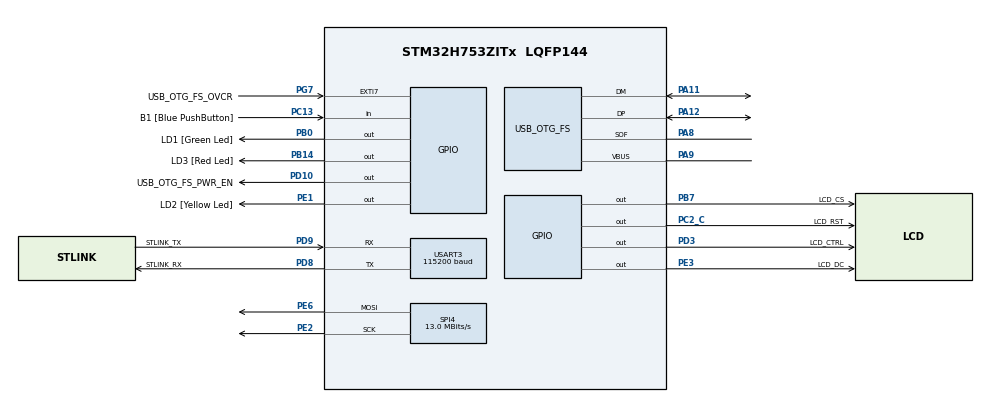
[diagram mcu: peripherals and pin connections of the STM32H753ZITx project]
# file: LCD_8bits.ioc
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CORTEX_M7.CPU_DCache=Disabled
CORTEX_M7.CPU_ICache=Disabled
CORTEX_M7.MPU_Control=__NULL
Mcu.Family=STM32H7
Mcu.Name=STM32H753ZITx
Mcu.Package=LQFP144
NVIC.PriorityGroup=NVIC_PRIORITYGROUP_4
PA1.Signal=ETH_REF_CLK
PA11.Mode=Device_Only
PA11.Signal=USB_OTG_FS_DM
PA12.Mode=Device_Only
PA12.Signal=USB_OTG_FS_DP
PA2.Signal=ETH_MDIO
PA7.Signal=ETH_CRS_DV
PA8.Mode=Activate_SOF_FS
PA8.Signal=USB_OTG_FS_SOF
PA9.Mode=Activate_VBUS
PA9.Signal=USB_OTG_FS_VBUS
PB0.GPIO_Label=LD1 [Green Led]
PB0.Signal=GPIO_Output
PB13.Signal=ETH_TXD1
PB14.GPIO_Label=LD3 [Red Led]
PB14.Signal=GPIO_Output
PB7.GPIO_FM7=__NULL
PB7.GPIO_Label=LCD_CS
PB7.GPIO_Speed=GPIO_SPEED_FREQ_HIGH
PB7.Signal=GPIO_Output
PC1.Signal=ETH_MDC
PC13.GPIO_Label=B1 [Blue PushButton]
PC13.Signal=GPIO_Input
PC14-OSC32_IN\ (OSC32_IN).Mode=LSE-External-Oscillator
PC14-OSC32_IN\ (OSC32_IN).Signal=RCC_OSC32_IN
PC15-OSC32_OUT\ (OSC32_OUT).Mode=LSE-External-Oscillator
PC15-OSC32_OUT\ (OSC32_OUT).Signal=RCC_OSC32_OUT
PC2_C.GPIO_Label=LCD_RST
PC2_C.GPIO_Speed=GPIO_SPEED_FREQ_HIGH
PC2_C.PinState=GPIO_PIN_SET
PC2_C.Signal=GPIO_Output
PC4.Signal=ETH_RXD0
PC5.Signal=ETH_RXD1
PD10.GPIO_Label=USB_OTG_FS_PWR_EN
PD10.Signal=GPIO_Output
PD3.GPIO_Label=LCD_CTRL
PD3.Signal=GPIO_Output
PD8.GPIO_Label=STLINK_RX
PD8.Mode=Asynchronous
PD8.Signal=USART3_TX
PD9.GPIO_Label=STLINK_TX
PD9.Mode=Asynchronous
PD9.Signal=USART3_RX
PE1.GPIO_Label=LD2 [Yellow Led]
PE1.Signal=GPIO_Output
PE2.Mode=TX_Only_Simplex_Unidirect_Master
PE2.Signal=SPI4_SCK
PE3.GPIO_Label=LCD_DC
PE3.Signal=GPIO_Output
PE6.Mode=TX_Only_Simplex_Unidirect_Master
PE6.Signal=SPI4_MOSI
PG11.Signal=ETH_TX_EN
PG13.Signal=ETH_TXD0
PG7.GPIO_Label=USB_OTG_FS_OVCR
PG7.Signal=GPXTI7
PH0-OSC_IN\ (PH0).Mode=HSE-External-Clock-Source
PH0-OSC_IN\ (PH0).Signal=RCC_OSC_IN
PH1-OSC_OUT\ (PH1).Signal=RCC_OSC_OUT
ProjectManager.HeapSize=0x2000
ProjectManager.StackSize=0x4000
ProjectManager.TargetToolchain=MDK-ARM V5.32
RCC.ADCFreq_Value=16375000
RCC.APB1Freq_Value=52000000
RCC.APB2Freq_Value=52000000
RCC.APB3Freq_Value=104000000
RCC.APB4Freq_Value=104000000
RCC.CortexFreq_Value=26000000
RCC.Cortex_Div=SYSTICK_CLKSOURCE_HCLK_DIV8
RCC.D2PPRE1=RCC_APB1_DIV2
RCC.D2PPRE2=RCC_APB2_DIV2
RCC.DIVM1=1
RCC.DIVN1=52
RCC.DIVN2=131
RCC.DIVQ1=7
RCC.HCLKFreq_Value=104000000
RCC.HPRE=RCC_HCLK_DIV2
RCC.HSE_VALUE=8000000
RCC.PLLFRACN=0
RCC.PWR_Regulator_Voltage_Scale=PWR_REGULATOR_VOLTAGE_SCALE2
RCC.SYSCLKFreq_VALUE=208000000
RCC.SYSCLKSource=RCC_SYSCLKSOURCE_PLLCLK
RCC.USBFreq_Value=59428571.428571425
SPI4.BaudRatePrescaler=SPI_BAUDRATEPRESCALER_4
SPI4.CalculateBaudRate=13.0 MBits/s
SPI4.DataSize=SPI_DATASIZE_16BIT
SPI4.Direction=SPI_DIRECTION_2LINES_TXONLY
SPI4.Mode=SPI_MODE_MASTER
SPI4.VirtualType=VM_MASTER
USART3.AutoBaudRateEnableParam=UART_ADVFEATURE_AUTOBAUDRATE_DISABLE
USART3.BaudRate=115200
USART3.ClockPrescaler=PRESCALER_DIV1
USART3.DMADisableonRxErrorParam=ADVFEATURE_DMA_ENABLEONRXERROR
USART3.DataInvertParam=ADVFEATURE_DATAINV_DISABLE
USART3.FIFOMode=FIFOMODE_DISABLE
USART3.MSBFirstParam=ADVFEATURE_MSBFIRST_DISABLE
USART3.Mode=MODE_TX_RX
USART3.OneBitSampling=UART_ONE_BIT_SAMPLE_DISABLE
USART3.OverSampling=UART_OVERSAMPLING_16
USART3.OverrunDisableParam=ADVFEATURE_OVERRUN_ENABLE
USART3.Parity=PARITY_NONE
USART3.RXFIFOThreshold=RXFIFO_THRESHOLD_1EIGHTHFULL
USART3.RxPinLevelInvertParam=ADVFEATURE_RXINV_DISABLE
USART3.StopBits=STOPBITS_1
USART3.SwapParam=ADVFEATURE_SWAP_DISABLE
USART3.TXFIFOThreshold=TXFIFO_THRESHOLD_1EIGHTHFULL
USART3.TxPinLevelInvertParam=ADVFEATURE_TXINV_DISABLE
USART3.VirtualMode-Asynchronous=VM_ASYNC
USART3.WordLength=WORDLENGTH_8B
USB_OTG_FS.Sof_enable=ENABLE
USB_OTG_FS.VirtualMode=Device_Only
USB_OTG_FS.battery_charging_enable=ENABLE
USB_OTG_FS.low_power_enable=DISABLE
USB_OTG_FS.lpm_enable=DISABLE
USB_OTG_FS.use_dedicated_ep1=DISABLE
USB_OTG_FS.vbus_sensing_enable=ENABLE
VP_CRC_VS_CRC.Mode=CRC_Activate
board=NUCLEO-H753ZI

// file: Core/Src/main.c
/* USER CODE BEGIN Header */
/**
  ******************************************************************************
  * @file           : main.c
  * @brief          : Main program body
  ******************************************************************************
  * @attention
  *
  * Copyright (c) 2024 STMicroelectronics.
  * All rights reserved.
  *
  * This software is licensed under terms that can be found in the LICENSE file
  * in the root directory of this software component.
  * If no LICENSE file comes with this software, it is provided AS-IS.
  *
  ******************************************************************************
  */
/* USER CODE END Header */
#include "main.h"

CRC_HandleTypeDef hcrc;

SPI_HandleTypeDef hspi4;

UART_HandleTypeDef huart3;

PCD_HandleTypeDef hpcd_USB_OTG_FS;

void SystemClock_Config(void);
static void MX_GPIO_Init(void);
static void MX_SPI4_Init(void);
static void MX_USART3_UART_Init(void);
static void MX_USB_OTG_FS_PCD_Init(void);
static void MX_CRC_Init(void);

/* USER CODE BEGIN 0 */
#include "SSD1289.h"
#include "SSD1289_string.h"
/* USER CODE END 0 */

int main(void)
{

  /* MCU Configuration--------------------------------------------------------*/

  /* Reset of all peripherals, Initializes the Flash interface and the Systick. */
  HAL_Init();

  /* Configure the system clock */
  SystemClock_Config();

  /* Initialize all configured peripherals */
  MX_GPIO_Init();
  MX_SPI4_Init();
  MX_USART3_UART_Init();
  MX_USB_OTG_FS_PCD_Init();
  MX_CRC_Init();
  /* USER CODE BEGIN 2 */
  SSD1289_handle ssd1289;
  const int figure_width = 240; //figure width by pixel
  const int figure_height = 320; //figure height by pixel
  uint16_t bit_array[] = {/*rgb565 data*/};

  SSD1289_init(&ssd1289, get_stm32H753_driver(), figure_width, figure_height);
  //SSD1289_set_window(&ssd1289, 0, 0, 32, 32);
  //SSD1289_transmit_to_ram(&ssd1289, bit_array, figure_width * figure_height * sizeof(uint16_t));

  SSD1289_clear(&ssd1289, 0x0000);
  SSD1289_put_str(&ssd1289, 0, 0, "fuck you mcu", 0x9999);

  /* USER CODE END 2 */

  /* Infinite loop */
  while (1)
  {

  }
}

void SystemClock_Config(void)
{
  RCC_OscInitTypeDef RCC_OscInitStruct = {0};
  RCC_ClkInitTypeDef RCC_ClkInitStruct = {0};

  /** Supply configuration update enable
  */
  HAL_PWREx_ConfigSupply(PWR_LDO_SUPPLY);

  /** Configure the main internal regulator output voltage
  */
  __HAL_PWR_VOLTAGESCALING_CONFIG(PWR_REGULATOR_VOLTAGE_SCALE2);

  while(!__HAL_PWR_GET_FLAG(PWR_FLAG_VOSRDY)) {}

  /** Initializes the RCC Oscillators according to the specified parameters
  * in the RCC_OscInitTypeDef structure.
  */
  RCC_OscInitStruct.OscillatorType = RCC_OSCILLATORTYPE_HSE;
  RCC_OscInitStruct.HSEState = RCC_HSE_BYPASS;
  RCC_OscInitStruct.PLL.PLLState = RCC_PLL_ON;
  RCC_OscInitStruct.PLL.PLLSource = RCC_PLLSOURCE_HSE;
  RCC_OscInitStruct.PLL.PLLM = 1;
  RCC_OscInitStruct.PLL.PLLN = 52;
  RCC_OscInitStruct.PLL.PLLP = 2;
  RCC_OscInitStruct.PLL.PLLQ = 7;
  RCC_OscInitStruct.PLL.PLLR = 2;
  RCC_OscInitStruct.PLL.PLLRGE = RCC_PLL1VCIRANGE_3;
  RCC_OscInitStruct.PLL.PLLVCOSEL = RCC_PLL1VCOWIDE;
  RCC_OscInitStruct.PLL.PLLFRACN = 0;
  if (HAL_RCC_OscConfig(&RCC_OscInitStruct) != HAL_OK)
  {
    Error_Handler();
  }

  /** Initializes the CPU, AHB and APB buses clocks
  */
  RCC_ClkInitStruct.ClockType = RCC_CLOCKTYPE_HCLK|RCC_CLOCKTYPE_SYSCLK
                              |RCC_CLOCKTYPE_PCLK1|RCC_CLOCKTYPE_PCLK2
                              |RCC_CLOCKTYPE_D3PCLK1|RCC_CLOCKTYPE_D1PCLK1;
  RCC_ClkInitStruct.SYSCLKSource = RCC_SYSCLKSOURCE_PLLCLK;
  RCC_ClkInitStruct.SYSCLKDivider = RCC_SYSCLK_DIV1;
  RCC_ClkInitStruct.AHBCLKDivider = RCC_HCLK_DIV2;
  RCC_ClkInitStruct.APB3CLKDivider = RCC_APB3_DIV1;
  RCC_ClkInitStruct.APB1CLKDivider = RCC_APB1_DIV2;
  RCC_ClkInitStruct.APB2CLKDivider = RCC_APB2_DIV2;
  RCC_ClkInitStruct.APB4CLKDivider = RCC_APB4_DIV1;

  if (HAL_RCC_ClockConfig(&RCC_ClkInitStruct, FLASH_LATENCY_1) != HAL_OK)
  {
    Error_Handler();
  }
}

static void MX_CRC_Init(void)
{

  hcrc.Instance = CRC;
  hcrc.Init.DefaultPolynomialUse = DEFAULT_POLYNOMIAL_ENABLE;
  hcrc.Init.DefaultInitValueUse = DEFAULT_INIT_VALUE_ENABLE;
  hcrc.Init.InputDataInversionMode = CRC_INPUTDATA_INVERSION_NONE;
  hcrc.Init.OutputDataInversionMode = CRC_OUTPUTDATA_INVERSION_DISABLE;
  hcrc.InputDataFormat = CRC_INPUTDATA_FORMAT_BYTES;
  if (HAL_CRC_Init(&hcrc) != HAL_OK)
  {
    Error_Handler();
  }

}

static void MX_SPI4_Init(void)
{

  /* SPI4 parameter configuration*/
  hspi4.Instance = SPI4;
  hspi4.Init.Mode = SPI_MODE_MASTER;
  hspi4.Init.Direction = SPI_DIRECTION_2LINES_TXONLY;
  hspi4.Init.DataSize = SPI_DATASIZE_16BIT;
  hspi4.Init.CLKPolarity = SPI_POLARITY_LOW;
  hspi4.Init.CLKPhase = SPI_PHASE_1EDGE;
  hspi4.Init.NSS = SPI_NSS_SOFT;
  hspi4.Init.BaudRatePrescaler = SPI_BAUDRATEPRESCALER_4;
  hspi4.Init.FirstBit = SPI_FIRSTBIT_MSB;
  hspi4.Init.TIMode = SPI_TIMODE_DISABLE;
  hspi4.Init.CRCCalculation = SPI_CRCCALCULATION_DISABLE;
  hspi4.Init.CRCPolynomial = 0x0;
  hspi4.Init.NSSPMode = SPI_NSS_PULSE_ENABLE;
  hspi4.Init.NSSPolarity = SPI_NSS_POLARITY_LOW;
  hspi4.Init.FifoThreshold = SPI_FIFO_THRESHOLD_01DATA;
  hspi4.Init.TxCRCInitializationPattern = SPI_CRC_INITIALIZATION_ALL_ZERO_PATTERN;
  hspi4.Init.RxCRCInitializationPattern = SPI_CRC_INITIALIZATION_ALL_ZERO_PATTERN;
  hspi4.Init.MasterSSIdleness = SPI_MASTER_SS_IDLENESS_00CYCLE;
  hspi4.Init.MasterInterDataIdleness = SPI_MASTER_INTERDATA_IDLENESS_00CYCLE;
  hspi4.Init.MasterReceiverAutoSusp = SPI_MASTER_RX_AUTOSUSP_DISABLE;
  hspi4.Init.MasterKeepIOState = SPI_MASTER_KEEP_IO_STATE_DISABLE;
  hspi4.Init.IOSwap = SPI_IO_SWAP_DISABLE;
  if (HAL_SPI_Init(&hspi4) != HAL_OK)
  {
    Error_Handler();
  }

}

static void MX_USART3_UART_Init(void)
{

  huart3.Instance = USART3;
  huart3.Init.BaudRate = 115200;
  huart3.Init.WordLength = UART_WORDLENGTH_8B;
  huart3.Init.StopBits = UART_STOPBITS_1;
  huart3.Init.Parity = UART_PARITY_NONE;
  huart3.Init.Mode = UART_MODE_TX_RX;
  huart3.Init.HwFlowCtl = UART_HWCONTROL_NONE;
  huart3.Init.OverSampling = UART_OVERSAMPLING_16;
  huart3.Init.OneBitSampling = UART_ONE_BIT_SAMPLE_DISABLE;
  huart3.Init.ClockPrescaler = UART_PRESCALER_DIV1;
  huart3.AdvancedInit.AdvFeatureInit = UART_ADVFEATURE_NO_INIT;
  if (HAL_UART_Init(&huart3) != HAL_OK)
  {
    Error_Handler();
  }
  if (HAL_UARTEx_SetTxFifoThreshold(&huart3, UART_TXFIFO_THRESHOLD_1_8) != HAL_OK)
  {
    Error_Handler();
  }
  if (HAL_UARTEx_SetRxFifoThreshold(&huart3, UART_RXFIFO_THRESHOLD_1_8) != HAL_OK)
  {
    Error_Handler();
  }
  if (HAL_UARTEx_DisableFifoMode(&huart3) != HAL_OK)
  {
    Error_Handler();
  }

}

static void MX_USB_OTG_FS_PCD_Init(void)
{

  hpcd_USB_OTG_FS.Instance = USB_OTG_FS;
  hpcd_USB_OTG_FS.Init.dev_endpoints = 9;
  hpcd_USB_OTG_FS.Init.speed = PCD_SPEED_FULL;
  hpcd_USB_OTG_FS.Init.dma_enable = DISABLE;
  hpcd_USB_OTG_FS.Init.phy_itface = PCD_PHY_EMBEDDED;
  hpcd_USB_OTG_FS.Init.Sof_enable = ENABLE;
  hpcd_USB_OTG_FS.Init.low_power_enable = DISABLE;
  hpcd_USB_OTG_FS.Init.lpm_enable = DISABLE;
  hpcd_USB_OTG_FS.Init.battery_charging_enable = ENABLE;
  hpcd_USB_OTG_FS.Init.vbus_sensing_enable = ENABLE;
  hpcd_USB_OTG_FS.Init.use_dedicated_ep1 = DISABLE;
  if (HAL_PCD_Init(&hpcd_USB_OTG_FS) != HAL_OK)
  {
    Error_Handler();
  }

}

static void MX_GPIO_Init(void)
{
  GPIO_InitTypeDef GPIO_InitStruct = {0};

  /* GPIO Ports Clock Enable */
  __HAL_RCC_GPIOE_CLK_ENABLE();
  __HAL_RCC_GPIOC_CLK_ENABLE();
  __HAL_RCC_GPIOH_CLK_ENABLE();
  __HAL_RCC_GPIOA_CLK_ENABLE();
  __HAL_RCC_GPIOB_CLK_ENABLE();
  __HAL_RCC_GPIOD_CLK_ENABLE();
  __HAL_RCC_GPIOG_CLK_ENABLE();

  /*Configure GPIO pin Output Level */
  HAL_GPIO_WritePin(GPIOE, LCD_DC_Pin|LD2_Pin, GPIO_PIN_RESET);

  /*Configure GPIO pin Output Level */
  HAL_GPIO_WritePin(LCD_RST_GPIO_Port, LCD_RST_Pin, GPIO_PIN_SET);

  /*Configure GPIO pin Output Level */
  HAL_GPIO_WritePin(GPIOB, LD1_Pin|LD3_Pin|LCD_CS_Pin, GPIO_PIN_RESET);

  /*Configure GPIO pin Output Level */
  HAL_GPIO_WritePin(GPIOD, USB_OTG_FS_PWR_EN_Pin|LCD_CTRL_Pin, GPIO_PIN_RESET);

  /*Configure GPIO pins : LCD_DC_Pin LD2_Pin */
  GPIO_InitStruct.Pin = LCD_DC_Pin|LD2_Pin;
  GPIO_InitStruct.Mode = GPIO_MODE_OUTPUT_PP;
  GPIO_InitStruct.Pull = GPIO_NOPULL;
  GPIO_InitStruct.Speed = GPIO_SPEED_FREQ_LOW;
  HAL_GPIO_Init(GPIOE, &GPIO_InitStruct);

  /*Configure GPIO pin : B1_Pin */
  GPIO_InitStruct.Pin = B1_Pin;
  GPIO_InitStruct.Mode = GPIO_MODE_INPUT;
  GPIO_InitStruct.Pull = GPIO_NOPULL;
  HAL_GPIO_Init(B1_GPIO_Port, &GPIO_InitStruct);

  /*Configure GPIO pins : PC1 PC4 PC5 */
  GPIO_InitStruct.Pin = GPIO_PIN_1|GPIO_PIN_4|GPIO_PIN_5;
  GPIO_InitStruct.Mode = GPIO_MODE_AF_PP;
  GPIO_InitStruct.Pull = GPIO_NOPULL;
  GPIO_InitStruct.Speed = GPIO_SPEED_FREQ_LOW;
  GPIO_InitStruct.Alternate = GPIO_AF11_ETH;
  HAL_GPIO_Init(GPIOC, &GPIO_InitStruct);

  /*Configure GPIO pin : LCD_RST_Pin */
  GPIO_InitStruct.Pin = LCD_RST_Pin;
  GPIO_InitStruct.Mode = GPIO_MODE_OUTPUT_PP;
  GPIO_InitStruct.Pull = GPIO_NOPULL;
  GPIO_InitStruct.Speed = GPIO_SPEED_FREQ_HIGH;
  HAL_GPIO_Init(LCD_RST_GPIO_Port, &GPIO_InitStruct);

  /*Configure GPIO pins : PA1 PA2 PA7 */
  GPIO_InitStruct.Pin = GPIO_PIN_1|GPIO_PIN_2|GPIO_PIN_7;
  GPIO_InitStruct.Mode = GPIO_MODE_AF_PP;
  GPIO_InitStruct.Pull = GPIO_NOPULL;
  GPIO_InitStruct.Speed = GPIO_SPEED_FREQ_LOW;
  GPIO_InitStruct.Alternate = GPIO_AF11_ETH;
  HAL_GPIO_Init(GPIOA, &GPIO_InitStruct);

  /*Configure GPIO pins : LD1_Pin LD3_Pin */
  GPIO_InitStruct.Pin = LD1_Pin|LD3_Pin;
  GPIO_InitStruct.Mode = GPIO_MODE_OUTPUT_PP;
  GPIO_InitStruct.Pull = GPIO_NOPULL;
  GPIO_InitStruct.Speed = GPIO_SPEED_FREQ_LOW;
  HAL_GPIO_Init(GPIOB, &GPIO_InitStruct);

  /*Configure GPIO pin : PB13 */
  GPIO_InitStruct.Pin = GPIO_PIN_13;
  GPIO_InitStruct.Mode = GPIO_MODE_AF_PP;
  GPIO_InitStruct.Pull = GPIO_NOPULL;
  GPIO_InitStruct.Speed = GPIO_SPEED_FREQ_LOW;
  GPIO_InitStruct.Alternate = GPIO_AF11_ETH;
  HAL_GPIO_Init(GPIOB, &GPIO_InitStruct);

  /*Configure GPIO pins : USB_OTG_FS_PWR_EN_Pin LCD_CTRL_Pin */
  GPIO_InitStruct.Pin = USB_OTG_FS_PWR_EN_Pin|LCD_CTRL_Pin;
  GPIO_InitStruct.Mode = GPIO_MODE_OUTPUT_PP;
  GPIO_InitStruct.Pull = GPIO_NOPULL;
  GPIO_InitStruct.Speed = GPIO_SPEED_FREQ_LOW;
  HAL_GPIO_Init(GPIOD, &GPIO_InitStruct);

  /*Configure GPIO pin : USB_OTG_FS_OVCR_Pin */
  GPIO_InitStruct.Pin = USB_OTG_FS_OVCR_Pin;
  GPIO_InitStruct.Mode = GPIO_MODE_IT_RISING;
  GPIO_InitStruct.Pull = GPIO_NOPULL;
  HAL_GPIO_Init(USB_OTG_FS_OVCR_GPIO_Port, &GPIO_InitStruct);

  /*Configure GPIO pins : PG11 PG13 */
  GPIO_InitStruct.Pin = GPIO_PIN_11|GPIO_PIN_13;
  GPIO_InitStruct.Mode = GPIO_MODE_AF_PP;
  GPIO_InitStruct.Pull = GPIO_NOPULL;
  GPIO_InitStruct.Speed = GPIO_SPEED_FREQ_LOW;
  GPIO_InitStruct.Alternate = GPIO_AF11_ETH;
  HAL_GPIO_Init(GPIOG, &GPIO_InitStruct);

  /*Configure GPIO pin : LCD_CS_Pin */
  GPIO_InitStruct.Pin = LCD_CS_Pin;
  GPIO_InitStruct.Mode = GPIO_MODE_OUTPUT_PP;
  GPIO_InitStruct.Pull = GPIO_NOPULL;
  GPIO_InitStruct.Speed = GPIO_SPEED_FREQ_HIGH;
  HAL_GPIO_Init(LCD_CS_GPIO_Port, &GPIO_InitStruct);

}

void Error_Handler(void)
{
  __disable_irq();
  while (1)
  {
  }
}
